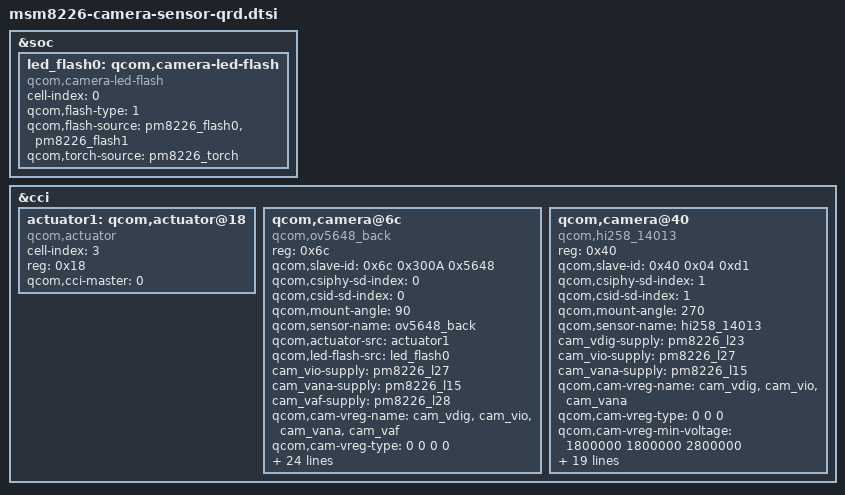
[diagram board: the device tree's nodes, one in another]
/*
 * Copyright (c) 2013, The Linux Foundation. All rights reserved.
 *
 * This program is free software; you can redistribute it and/or modify
 * it under the terms of the GNU General Public License version 2 and
 * only version 2 as published by the Free Software Foundation.
 *
 * This program is distributed in the hope that it will be useful,
 * but WITHOUT ANY WARRANTY; without even the implied warranty of
 * MERCHANTABILITY or FITNESS FOR A PARTICULAR PURPOSE.  See the
 * GNU General Public License for more details.
 */

&soc {
	led_flash0: qcom,camera-led-flash {
		cell-index = <0>;
		compatible = "qcom,camera-led-flash";
		qcom,flash-type = <1>;
		qcom,flash-source = <&pm8226_flash0 &pm8226_flash1>;
		qcom,torch-source = <&pm8226_torch>;
	};
};

&cci {
	actuator1: qcom,actuator@18 {
		cell-index = <3>;
		reg = <0x18>;
		compatible = "qcom,actuator";
		qcom,cci-master = <0>;
	};

/*	
	qcom,camera@20 {
		compatible = "qcom,imx214";
		reg = <0x20>;
		qcom,slave-id = <0x20 0x0016 0x214>;
		qcom,csiphy-sd-index = <0>;
		qcom,csid-sd-index = <0>;
		qcom,actuator-src = <&actuator1>;
		qcom,led-flash-src = <&led_flash0>;
		qcom,mount-angle = <90>;
		qcom,sensor-name = "imx214";
		cam_vdig-supply = <&pm8226_l5>;
		cam_vana-supply = <&pm8226_l15>;
		cam_vio-supply = <&pm8226_l27>;
		cam_vaf-supply = <&pm8226_l28>;
		qcom,cam-vreg-name = "cam_vdig", "cam_vio", "cam_vana",
							 "cam_vaf";
		qcom,cam-vreg-type = <0 0 0 0>;
		qcom,cam-vreg-min-voltage = <1000000 1800000 2700000 2800000>;
		qcom,cam-vreg-max-voltage = <1000000 1800000 2700000 2800000>;
		qcom,cam-vreg-op-mode = <105000 200000 80000 100000>;
		qcom,gpio-no-mux = <0>;
		gpios = <&msmgpio 26 0>,
			<&msmgpio 37 0>;	
		qcom,gpio-reset = <1>;		
		qcom,gpio-req-tbl-num = <0 1 >;
		qcom,gpio-req-tbl-flags = <1 0>;
		qcom,gpio-req-tbl-label = "CAMIF_MCLK",
					  "CAM_RESET1";					 
		qcom,gpio-set-tbl-num = <1 1>;
		qcom,gpio-set-tbl-flags = <0 2>;
		qcom,gpio-set-tbl-delay = <1000 30000>;
		qcom,csi-lane-assign = <0x4320>;
		qcom,csi-lane-mask = <0x1F>;
		qcom,sensor-position = <0>;
		qcom,sensor-mode = <1>;
		qcom,cci-master = <0>;
		status = "ok";
	};
*/

//lxl modify 

	qcom,camera@6c{
			compatible = "qcom,ov5648_back";
			reg = <0x6c>;
			qcom,slave-id = <0x6c 0x300A 0x5648>;
			qcom,csiphy-sd-index = <0>;
			qcom,csid-sd-index = <0>;
			qcom,mount-angle = <90>;
			qcom,sensor-name = "ov5648_back";		
//lxl
		qcom,actuator-src = <&actuator1>;
		qcom,led-flash-src = <&led_flash0>;

			
			
			cam_vio-supply = <&pm8226_l27>;
			cam_vana-supply = <&pm8226_l15>;
			cam_vaf-supply = <&pm8226_l28>;
			
			qcom,cam-vreg-name = "cam_vdig", "cam_vio", "cam_vana","cam_vaf";
			qcom,cam-vreg-type = <0 0 0 0>;
			qcom,cam-vreg-min-voltage = <1800000 1800000 2800000 2800000 >;
			qcom,cam-vreg-max-voltage = <1800000 1800000 2800000 2800000 >;
			qcom,cam-vreg-op-mode = <200000 2000000 100000 100000 >;
			qcom,gpio-no-mux = <0>;

			gpios = <&msmgpio 26 0>,				
				    <&msmgpio 37 0>,
				    <&msmgpio 36 0>,
				    <&msmgpio 35 0>; //lxl add 
				    
			qcom,gpio-reset = <1>;
			qcom,gpio-standby = <2>;
			  
                     qcom,gpio-vana = <3>; //front pwdn pin  // lxl add  
			
			qcom,gpio-req-tbl-num = <0 1 2 3>;
			qcom,gpio-req-tbl-flags = <1 0 0 0>;
			qcom,gpio-req-tbl-label = "CAMIF_MCLK",
						  "CAM_RESET1",
						  "CAM_STANDBY",
						   "CAM_front_pwdn";
			qcom,gpio-set-tbl-num = <1 1>;
			qcom,gpio-set-tbl-flags = <0 2>;
			qcom,gpio-set-tbl-delay = <1000 4000>;
			qcom,csi-lane-assign = <0x4320>;
//			qcom,csi-lane-mask = <0x3>;
//		qcom,csi-lane-assign = <0x4320>;
		qcom,csi-lane-mask = <0x07>;
		
			qcom,sensor-position = <0>;
			qcom,sensor-mode = <1>;
			qcom,cci-master = <0>;
			status = "ok";
		};

	qcom,camera@40{
			compatible = "qcom,hi258_14013";
			reg = <0x40>;
			qcom,slave-id = <0x40 0x04 0xd1>;
			qcom,csiphy-sd-index = <1>;
			qcom,csid-sd-index = <1>;
			qcom,mount-angle = <270>;
			qcom,sensor-name = "hi258_14013";	
			cam_vdig-supply = <&pm8226_l23>; // 28		
			cam_vio-supply = <&pm8226_l27>;
			cam_vana-supply = <&pm8226_l15>;
			qcom,cam-vreg-name = "cam_vdig","cam_vio","cam_vana" ;
			qcom,cam-vreg-type = <0 0 0>;
			qcom,cam-vreg-min-voltage = <1800000 1800000 2800000 >;
			qcom,cam-vreg-max-voltage = <1800000 1800000 2800000 >;
			qcom,cam-vreg-op-mode = <200000 200000 100000 >;
			qcom,gpio-no-mux = <0>;

			gpios = <&msmgpio 26 0>,				
				    <&msmgpio 28 0>,
				    <&msmgpio 35 0>;
				    
			qcom,gpio-reset = <1>;
			qcom,gpio-standby = <2>;
			qcom,gpio-req-tbl-num = <0 1 2>;
			qcom,gpio-req-tbl-flags = <1 0 0>;
			qcom,gpio-req-tbl-label = "CAMIF_MCLK",
						  "CAM_RESET1",
						  "CAM_STANDBY";
			qcom,gpio-set-tbl-num = <1 1>;
			qcom,gpio-set-tbl-flags = <0 2>;
			qcom,gpio-set-tbl-delay = <1000 4000>;
			qcom,csi-lane-assign = <0x4320>;
			qcom,csi-lane-mask = <0x3>;
			qcom,sensor-position = <1>;
			qcom,sensor-mode = <1>;
			qcom,cci-master = <0>;
			status = "ok";
		};

// lxl modify end

/* OPPO 2014-01-09 zhangzr Add end */
};
